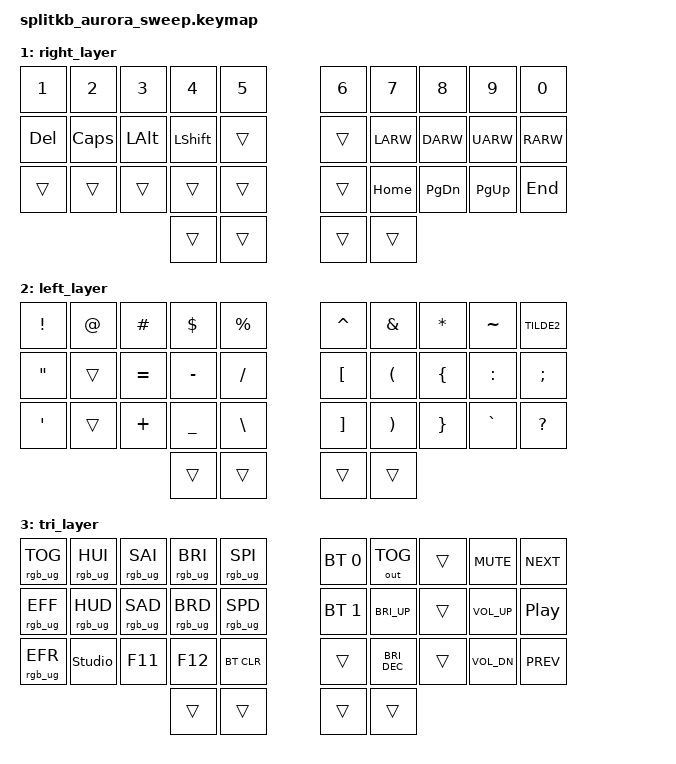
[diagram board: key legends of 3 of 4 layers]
// Copyright (c) 2022 The ZMK Contributors
// SPDX-License-Identifier: MIT

#include <behaviors.dtsi>
#include <dt-bindings/zmk/keys.h>
#include <dt-bindings/zmk/bt.h>
#include <dt-bindings/zmk/outputs.h>
#include <dt-bindings/zmk/rgb.h>

// Home row mods macro
#define HRML(k2,k3,k4) &ht LGUI k2  &ht LALT k3  &ht LSHIFT k4
#define HRMR(k1,k2,k3) &ht RSHIFT k1  &ht RALT k2  &ht RGUI k3

#define LAY_DEF 0
#define LAY_RIG 1
#define LAY_LEF 2
#define LAY_TRI 3

&led_strip { chain-length = <23>; };

/ {
    combos {
        compatible = "zmk,combos";

        combo_esc {
            timeout-ms = <50>;
            key-positions = <0 1>;
            bindings = <&kp ESC>;
        };

        combo_toggle_app {
            timeout-ms = <50>;
            key-positions = <10 11>;
            bindings = <&alt_tab>;
        };

    };

    macros {
        alt_tab: alt_tab {
            label = "alt_tab";
            compatible = "zmk,behavior-macro";
            #binding-cells = <0>;
            bindings
                = <&macro_press &kp LALT>
                , <&macro_tap &kp TAB>
                , <&macro_release &kp LALT>
                ;
        };
    };

    behaviors {
        ht: hold_tap {
            label = "hold_tap";
            compatible = "zmk,behavior-hold-tap";
            #binding-cells = <2>;
            flavor = "tap-preferred";
            tapping-term-ms = <220>;
            quick-tap-ms = <150>;
            global-quick-tap;
            bindings = <&kp>, <&kp>;
        };
    };

    conditional_layers {
        compatible = "zmk,conditional-layers";
        tri_layer {
            if-layers = <LAY_RIG LAY_LEF>;
            then-layer = <LAY_TRI>;
        };
    };

    keymap {
        compatible = "zmk,keymap";
        default_layer {
            bindings = <
        //╭──────────┬──────────┬──────────┬──────────┬──────────╮   ╭──────────┬──────────┬──────────┬──────────┬──────────╮
        //│  Q       │  W       │  E       │  R       │  T       │   │  Y       │  U       │  I       │  O       │  P       │
            &kp Q      &kp W      &kp E      &kp R      &kp T          &kp Y      &kp U      &kp I      &kp O      &kp P
        //├──────────┼──────────┼──────────┼──────────┼──────────┤   ├──────────┼──────────┼──────────┼──────────┼──────────┤
        //│  A       │  S       │  D       │  F       │  G       │   │  H       │  J       │  K       │  L       │BACKSPACE │
            &kp A      HRML(S,         D,         F)     &kp G          &kp H      HRMR(J,        K,           L)   &kp BSPC
        //├──────────┼──────────┼──────────┼──────────┼──────────┤   ├──────────┼──────────┼──────────┼──────────┼──────────┤
        //│  Z       │  X       │  C       │  V       │  B       │   │  N       │  M       │ , <      │ . >      │ ENTER    │
            &kp Z      &kp X      &kp C      &kp V      &kp B          &kp N      &kp M      &kp COMMA  &kp DOT    &kp ENTER
        //╰──────────┴──────────┴──────────┼──────────┼──────────┤   ├──────────┼──────────┼──────────┴──────────┴──────────╯
                                        &kp LGUI   &lt LAY_LEF TAB   &lt LAY_RIG SPACE &lt LAY_RIG RSHIFT
        //                                 ╰──────────┴──────────╯   ╰──────────┴──────────╯
            >;
        };

        right_layer {
            bindings = <
        //╭──────────┬──────────┬──────────┬──────────┬──────────╮   ╭──────────┬──────────┬──────────┬──────────┬──────────╮
        //│ 1        │  2       │  3       │  4       │  5       │   │ 6        │ 7        │ 8        │ 9        │   0      │
            &kp N1    &kp N2     &kp N3     &kp N4     &kp N5          &kp N6     &kp N7     &kp N8     &kp N9      &kp N0
        //├──────────┼──────────┼──────────┼──────────┼──────────┤   ├──────────┼──────────┼──────────┼──────────┼──────────┤
        //│ DELETE   │ CapsLock │   Alt    │  Shift   │          |   |          │ LEFT     │ DOWN     │ UP       │ RIGHT    │
            &kp DEL   &kp CAPS   &kp LALT  &kp LSHIFT  &trans         &trans     &kp LARW   &kp DARW   &kp UARW   &kp RARW
        //├──────────┼──────────┼──────────┼──────────┼──────────┤   ├──────────┼──────────┼──────────┼──────────┼──────────┤
        //│          │          │          │          │          │   │          │ HOME     │ PAGE DN  │ PAGE UP  │ END      │
            &trans    &trans     &trans     &trans      &trans           &trans     &kp HOME   &kp PG_DN  &kp PG_UP  &kp END
        //╰──────────┴──────────┴──────────┼──────────┼──────────┤   ├──────────┼──────────┼──────────┴──────────┴──────────╯
                                             &trans     &trans         &trans     &trans
        //                                 ╰──────────┴──────────╯   ╰──────────┴──────────╯
            >;
        };

        left_layer {
            bindings = <
        //╭──────────┬──────────┬──────────┬──────────┬──────────╮   ╭──────────┬──────────┬──────────┬──────────┬──────────╮
        //│  !       │  @       │  #       │  $       │  %       │   │  ^       │  &       │  *       │  ~       │  │       │
            &kp EXCL   &kp AT     &kp HASH   &kp DLLR   &kp PRCNT      &kp CARET  &kp AMPS   &kp ASTRK  &kp TILDE  &kp TILDE2
        //├──────────┼──────────┼──────────┼──────────┼──────────┤   ├──────────┼──────────┼──────────┼──────────┼──────────┤
        //│  "       │          │  =       │  -       │  /       │   │  [       │  (       │  {       │     :    │  ;
             &kp DQT    &trans   &kp EQUAL  &kp MINUS    &kp FSLH       &kp LBKT   &kp LPAR  &kp LBRC   &kp COLON  &kp SEMI
        //├──────────┼──────────┼──────────┼──────────┼──────────┤   ├──────────┼──────────┼──────────┼──────────┼──────────┤
        //│  '       │          │  +       │  _       │  \       │   │  ]       │  )       │  }       │  `       │   ?      │
            &kp SQT     &trans     &kp PLUS   &kp UNDER  &kp BSLH       &kp RBKT   &kp RPAR  &kp RBRC   &kp GRAVE  &kp QMARK
        //╰──────────┴──────────┴──────────┼──────────┼──────────┤   ├──────────┼──────────┼──────────┴──────────┴──────────╯
                                             &trans     &trans         &trans     &trans
        //                                 ╰──────────┴──────────╯   ╰──────────┴──────────╯
            >;
        };

        tri_layer {
            bindings = <
        //╭───────────────┬───────────────┬───────────────┬────────────────┬───────────────╮   ╭────────────┬────────────┬──────────┬───────────┬──────────╮
        //│RGB on/off     │               │               │                │               │   │  PROFILE 0 │ TOGGLEOUT  │          │ VOL MUTE  │ NEXTSONG │
           &rgb_ug RGB_TOG &rgb_ug RGB_HUI &rgb_ug RGB_SAI &rgb_ug RGB_BRI  &rgb_ug RGB_SPI     &bt BT_SEL 0  &out OUT_TOG &trans    &kp C_MUTE  &kp C_NEXT
        //├───────────────┼───────────────┼───────────────┼────────────────┼───────────────┤   ├────────────┼────────────┼──────────┼───────────┼──────────┤
        //│  F5           │               │               │                │               │   │ PROFILE 1  │ INC BRIGHT │          │  VOL UP   │PAUSEMUSIC│
           &rgb_ug RGB_EFF &rgb_ug RGB_HUD &rgb_ug RGB_SAD &rgb_ug RGB_BRD  &rgb_ug RGB_SPD     &bt BT_SEL 1  &kp C_BRI_UP  &trans   &kp C_VOL_UP  &kp C_PP
        //├───────────────┼───────────────┼───────────────┼────────────────┼───────────────┤   ├────────────┼────────────┼──────────┼───────────┼──────────┤
        //│  F9           │ Unlock studio │  F11          │  F12           │  CLEAR BT     │   │            │ DEC BRIGHT │          |  VOL DOWN │ PREVSONG │
           &rgb_ug RGB_EFR  &studio_unlock   &kp F11         &kp F12          &bt BT_CLR         &trans       &kp C_BRI_DEC  &trans   &kp C_VOL_DN &kp C_PREV
        //╰───────────────┴───────────────┴───────────────┼────────────────┼───────────────┤   ├────────────┼────────────┼──────────┴───────────┴──────────╯
                                                                &trans         &trans              &trans       &trans
        //                                                ╰────────────────┴───────────────╯   ╰────────────┴────────────╯
            >;
        };
    };
};
